# STM32H733 register map
File version: 1.2
CPU: CM7 r0p1, little endian, MPU, FPU, 4 interrupt priority bits
Registers are 32-bit, read-write, reset 0x0 unless marked. A register's access mark holds for its fields unless they carry their own. Offsets are from the block's base; [hi:lo] are bit positions; lines under a group give offsets from that group; {n}, {i} and the like mark numbered series.

## OTG1_HS_PWRCLK — USB 1 on the go high speed
Base 0x40040E00
Same registers: OTG2_HS_PWRCLK 0x40080E00
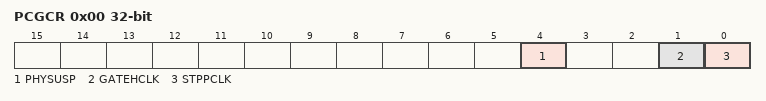
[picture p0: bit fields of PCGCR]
0x00 PCGCR — Power and clock gating control register
  [4] PHYSUSP — PHY suspended
  [1] GATEHCLK
  [0] STPPCLK — Stop PHY clock

## OctoSPII_O_Manager
Base 0x5200B400
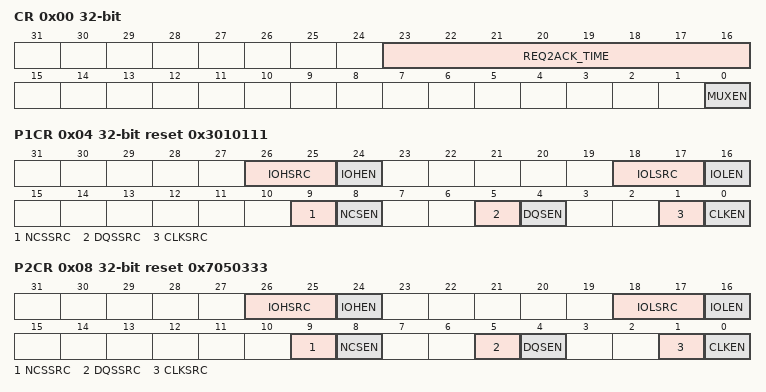
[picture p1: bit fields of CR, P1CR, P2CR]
0x00 CR — OctoSPI IO Manager Control Register
  [23:16] REQ2ACK_TIME — REQ to ACK Time
  [0] MUXEN — Multiplexed mode Enable
0x04 P1CR reset 0x3010111 — OctoSPI IO Manager Port 1 configuration register
  [26:25] IOHSRC
  [24] IOHEN
  [18:17] IOLSRC
  [16] IOLEN
  [9] NCSSRC
  [8] NCSEN
  [5] DQSSRC
  [4] DQSEN
  [1] CLKSRC — CLK/CLKn Source for Port n
  [0] CLKEN — CLK/CLKn Enable for Port n
0x08 P2CR reset 0x7050333 — OctoSPI IO Manager Port 2 configuration register
  [26:25] IOHSRC, [24] IOHEN, [18:17] IOLSRC, [16] IOLEN, [9] NCSSRC, [8] NCSEN, [5] DQSSRC, [4] DQSEN, [1] CLKSRC, [0] CLKEN

## RAMECC1 — ECC controller is associated to each RAM area
Base 0x52009000
Same registers: RAMECC2 0x48023000
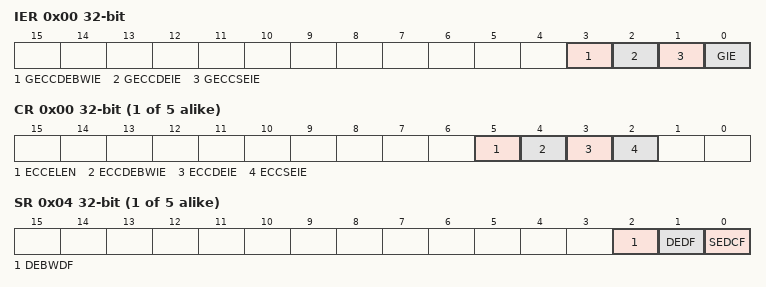
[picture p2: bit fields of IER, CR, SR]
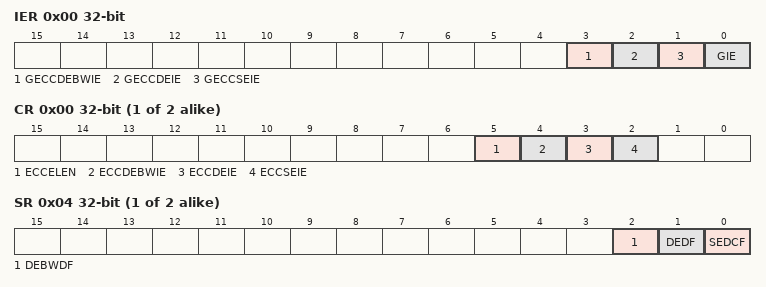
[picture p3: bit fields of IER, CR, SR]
0x00 IER — RAMECC interrupt enable register
  [3] GECCDEBWIE — Global ECC double error on byte write (BW) interrupt enable
  [2] GECCDEIE — Global ECC double error interrupt enable
  [1] GECCSEIE — Global ECC single error interrupt enable
  [0] GIE — Global interrupt enable
{0x0+0x20*i} M{i} (i=1..5) group — Cluster M{i}, containing M?CR, M?SR, M?FAR, M?FDRL, M?FDRH, M?FECR
  0x00 CR — RAMECC monitor x configuration register
    [5] ECCELEN — ECC error latching enable
    [4] ECCDEBWIE — ECC double error on byte write (BW) interrupt enable
    [3] ECCDEIE — ECC double error interrupt enable
    [2] ECCSEIE — ECC single error interrupt enable
  0x04 SR — RAMECC monitor x status register
    [2] DEBWDF — ECC double error on byte write (BW) detected flag
    [1] DEDF — ECC double error detected flag
    [0] SEDCF — ECC single error detected and corrected flag
  0x08 FAR ro — RAMECC monitor x failing address register
    [31:0] FADD — ECC error failing address
  0x0C FDRL ro — RAMECC monitor x failing data low register
    [31:0] FDATAL — Failing data low
  0x10 FDRH ro — RAMECC monitor x failing data high register
    [31:0] FDATAH — Failing data high (64-bit memory)
  0x14 FECR ro — RAMECC monitor x failing ECC error code register
    [31:0] FEC — Failing error code

## RAMECC3 — ECC controller is associated to each RAM area
Base 0x58027000
0x00 IER — RAMECC interrupt enable register
  [3] GECCDEBWIE — Global ECC double error on byte write (BW) interrupt enable
  [2] GECCDEIE — Global ECC double error interrupt enable
  [1] GECCSEIE — Global ECC single error interrupt enable
  [0] GIE — Global interrupt enable
{0x0+0x20*i} M{i} (i=1..2) group — Cluster M{i}, containing M?CR, M?SR, M?FAR, M?FDRL, M?FDRH, M?FECR
  0x00 CR — RAMECC monitor x configuration register
    [5] ECCELEN — ECC error latching enable
    [4] ECCDEBWIE — ECC double error on byte write (BW) interrupt enable
    [3] ECCDEIE — ECC double error interrupt enable
    [2] ECCSEIE — ECC single error interrupt enable
  0x04 SR — RAMECC monitor x status register
    [2] DEBWDF — ECC double error on byte write (BW) detected flag
    [1] DEDF — ECC double error detected flag
    [0] SEDCF — ECC single error detected and corrected flag
  0x08 FAR ro — RAMECC monitor x failing address register
    [31:0] FADD — ECC error failing address
  0x0C FDRL ro — RAMECC monitor x failing data low register
    [31:0] FDATAL — Failing data low
  0x10 FDRH ro — RAMECC monitor x failing data high register
    [31:0] FDATAH — Failing data high (64-bit memory)
  0x14 FECR ro — RAMECC monitor x failing ECC error code register
    [31:0] FEC — Failing error code
